# tviic2d6m register map
Vendor: Infineon Technologies; Series: TVIIC2D6M; File version: 1.0
CPU: CM7 r0p1, little endian, MPU, FPU, double-precision FPU, I-cache, D-cache, VTOR, ITCM, DTCM, 3 interrupt priority bits, 16 interrupts
Registers are 32-bit, read-write, reset 0x0 unless marked. A register's access mark holds for its fields unless they carry their own. Offsets are from the block's base; [hi:lo] are bit positions; <NAME> marks a mode.

## DAC0 — DAC
Base 0x40840000
0x00 CTL — Control
  [31] ENABLED — DAC IP enable: '0': Disabled. If DAC is disabled, all non-retained MMIO registers (e.g. the TX_FIFO_STATUS and INTR_TX registers) have their fields reset to their default value. SRAM content is not retained. Analog DAC output is disabled and powered down irrespective of DAC_EN. '1': Enabled.
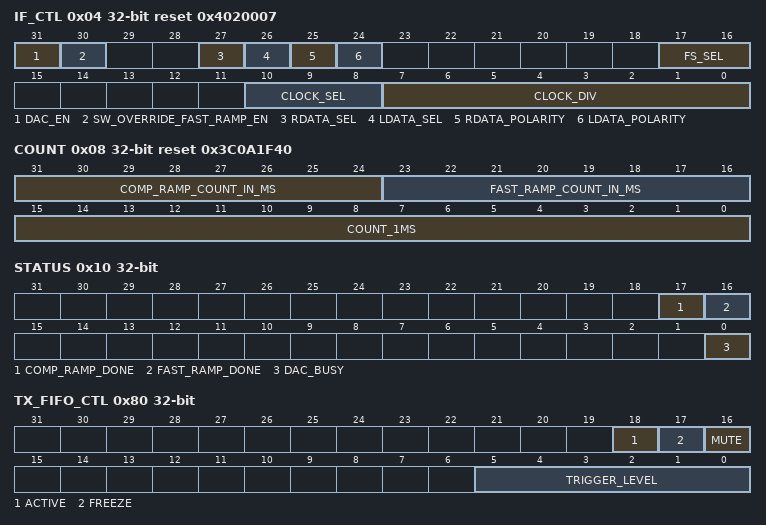
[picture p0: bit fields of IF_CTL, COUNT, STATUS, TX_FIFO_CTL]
0x04 IF_CTL reset 0x4020007 — Interface Control
  [31] DAC_EN — DAC Analog Enable. '0' - DAC Opamp and DAC COM analog bias generator is disabled. '1' - DAC Opamp and DAC COM analog bias generator is enabled. Note that after enabling the DAC Analog circuit, it requires 70ms to be stable. The same ramp up time applies when waking up from DeepSleep. DACEN is only valid when ENABLED=1. Note: This bit does not 'silent' the AudioDAC. CTL.ENABLED=0 is required to 'slient' the AudioDAC
  [30] SW_OVERRIDE_FAST_RAMP_EN — SW Override Fast Ramp enable. '0' - No SW override for fast ramp enable. HW controls the fast ramp enable. '1' - SW override for fast ramp enable. HW control is disabled. SW set the Fast Ramp enable before DAC_EN is set to 1. When SW override is used, 1. SW needs to disable the fast ramp enable by clearing this bit after the fast ramp up circuit is complete i.e. 10ms after setting DAC_EN. 2. After that, SW needs to ensure the DAC's stabilization time is met (i.e. 60ms after disabling the fast ramp circuit) before starting transactions to DAC.
  [27] RDATA_SEL — Right Data Selection. Specifies selection of the channel's 16-bit PCM data from the source FIFO data[31:0]: '0': data[15:0] (default setting). '1': data[31:16].
    0=DATA_LOW (N/A); 1=DATA_HIGH (N/A)
  [26] LDATA_SEL — Left Data Selection. Specifies selection of the channel's 16-bit PCM data from the source FIFO data[31:0]: '0': data[15:0]. '1': data[31:16] (default setting). Note: LDATA_SEL and RDATA_SEL are used to specify mono and stereo audio formats.
    0=DATA_LOW (N/A); 1=DATA_HIGH (N/A)
  [25] RDATA_POLARITY — Right Data polarity. '0' - No change in Right data. '1' - Invert (2's complement) Right data. The name of this field corresponds to the default setting. The function of this field always inverts bits 15:0 before the data is written into the FIFO. RDATA_SEL does not affect which bits are inverted.
  [24] LDATA_POLARITY — Left Data polarity. '0' - No change in Left data. '1' - Invert (2's complement) Left data. The name of this field corresponds to the default setting. The function of this field always inverts bits 31:16 before the data is written into the FIFO. LDATA_SEL does not affect which bits are inverted.
  [17:16] FS_SEL
    0=RSVD (N/A); 1=256FS_128OSR (N/A); 2=256FS_256OSR (N/A); 3=512FS_512OSR (N/A)
  [10:8] CLOCK_SEL — Interface clock clk_if selection: '0': SRSS clock clk_if_srss. '1'-'3': Clock 'clk_if' is off. '4': Master interface clock 'dac_mck'. '5'-'7': Clock 'clk_if' is off.
    0=SEL_SRSS_CLOCK (N/A); 1=SEL_CLK_IF_OFF (N/A); 4=SEL_DAC_MCK (N/A)
  [7:0] CLOCK_DIV — Interface clock divider (legal range [0, 255]). The DAC system clock clk_dac is defined as clk_if / (CLOCK_DIV + 1). CLOCK_DIV should be set to an odd value ([1,3,5,...255]) or 0 (divide by 1), to ensure a 50/50 percent duty cycle clock output. '0': clk_dac frequency is clk_if frequency (1 clk_dac cycle consists of 1 clk_if cycles). '1': clk_dac frequency is 1/2 clk_if frequency (1 clk_dac cycle consists of 2 clk_if cycles). '2': clk_dac frequency is 1/3 clk_if frequency. Note: results in a non 50/50 percent duty cycle. ... '255': clk_dac frequency is 1/256 clk_if frequency. Note: This field can only be changed when CLOCK_SEL= clk_if off.
0x08 COUNT reset 0x3C0A1F40
  [31:24] COMP_RAMP_COUNT_IN_MS — Complete Ramp count in ms. Specifies the number of counts in ms for the complete ramp circuit. The count takes place after the fast ramp count is complete. E.g. COMP_RAMP_COUNT_IN_MS=60 means that HW starts counting after disabling fast ramp circuit and stops counting after 60ms. HW sets STATUS.COMP_RAMP_DONE=1 after counting is complete.
  [23:16] FAST_RAMP_COUNT_IN_MS — Fast Ramp count in ms. Specifies the number of counts in ms for the fast ramp circuit. HW will enable the fast ramp circuit when counting is in progress. HW will disable the fast ramp circuit when counting is complete. E.g. FAST_RAMP_COUNT_IN_MS=10 means that HW enables the fast ramp circuit when it starts counting and disable the fast ramp circuit after 10ms. HW sets STATUS.FAST_RAMP_DONE=1 after counting is complete.
  [15:0] COUNT_1MS — Count for 1ms with clk_timer. Specifies the number of counts to achieve 1ms based on clk_timer (1 count represent 1 clk_timer period). This field needs to be programmed before IF_CTL.DAC_EN=1.
0x10 STATUS ro
  [17] COMP_RAMP_DONE — Complete Ramp Done. '0' - Complete Ramp is not complete. '1' - Complete Ramp is complete. The ramping of the circuit is deemed complete based on time specified in COMP_RAMP_COUNT_IN_MS. Timer starts counting if FAST_RAMP_DONE=1 and COMP_RAMP_DONE=0 and IF_CTL.DAC_EN=1 This bit transition from '0'->'1' will cause HW to set TX_INTR.RAMP_COMPLETE=1. SW clearing TX_INTR.RAMP_COMPLETE=0 will not have effect of this status bit.
  [16] FAST_RAMP_DONE — Fast Ramp Done. '0' - Fast ramping is not complete. '1' - Fast ramp circuit is complete. The fast ramp circuit is deemed complete based on time specified in FAST_RAMP_COUNT_IN_MS. Timer starts counting if FAST_RAMP_DONE=0 and IF_CTL.DAC_EN=1.
  [0] DAC_BUSY — DAC Busy. '0' - DAC is idle. '1' - Indicates that FS_SEL is in the middle of synchronizing to clk_if domain. SW must not change FS_SEL until DAC_BUSY=0.
0x80 TX_FIFO_CTL — TX FIFO control
  [18] ACTIVE — Activate functionality: '0': The FIFO_UNDERFLOW interrupt cause will not be activated. HW uses a constant PCM data value of '0' if ACTIVE=0 prior to FIFO content is available. Otherwise, PCM data is transmitted from the TX FIFO when finishing an audio packet stream. '1': The FIFO_UNDERFLOW interrupt may be activated (when an underflow event occurs). PCM data is transmitted from the TX FIFO. Note: This functionality is intended for startup for an audio packet stream when ACTIVE=0->1. PCM data is transmitted from the TX FIFO throughout ACTIVE=1. An audio packet stream ends when FIFO is empty and ACTIVE=0. HW uses a constant PCM data value of '0' if TX FIFO is empty regardless of ACTIVE=0/1.
  [17] FREEZE — Freeze functionality: '0': HW uses TX FIFO data and advances the FIFO read pointer. '1': HW uses a constant PCM data value of '0' (the FIFO data is not used). HW reads from the TX FIFO have no effect: freeze will not advance the FIFO read pointer. Note: This functionality is intended for debugging purposes.
  [16] MUTE — Mute functionality: '0': HW uses TX FIFO data. '1'- HW uses a constant PCM data value of '0'. Mute does advance the FIFO read pointer.
  [5:0] TRIGGER_LEVEL — Trigger level. When the TX FIFO has less entries than the number of this field, a transmitter trigger event is generated: - INTR_TX.FIFO_TRIGGER = (# FIFO entries < TRIGGER_LEVEL) Note: Setting TRIGGER_LEVEL=0 means trigger will not be set.
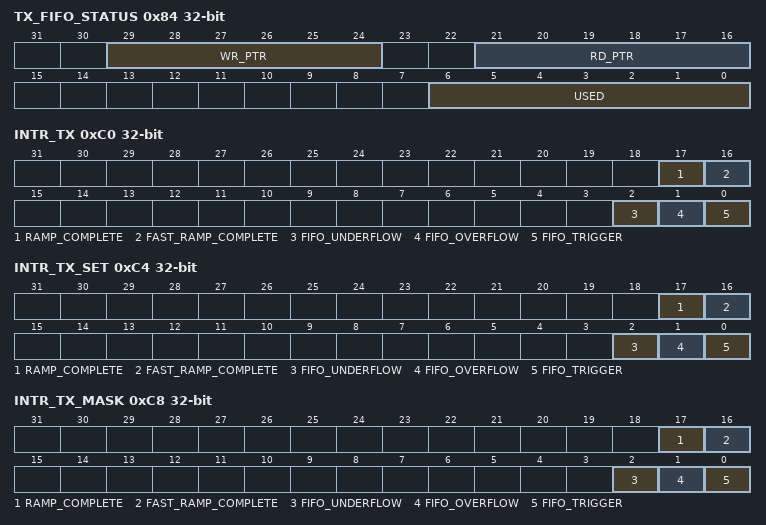
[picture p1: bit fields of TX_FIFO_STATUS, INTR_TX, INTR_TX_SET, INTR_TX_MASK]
0x84 TX_FIFO_STATUS ro
  [29:24] WR_PTR — TX FIFO write pointer: FIFO location at which a new data is written by the hardware. Note: This functionality is intended for debugging purposes.
  [21:16] RD_PTR — TX FIFO read pointer: FIFO location from which a data is read. Note: This functionality is intended for debugging purposes.
  [6:0] USED — Number of used/occupied entries in the TX FIFO. The field value is in the range [0, 64]. When '0', the FIFO is empty. When '64', the FIFO is full.
0x88 TX_FIFO_WR wo — TX FIFO write
  [31:0] DATA — Data written to the TX FIFO. Writing adds the data to the TX FIFO; i.e. behavior is similar to that of a PUSH operation (TX_FIFO_STATUS.WR_PTR is incremented and TX_FIFO_STATUS.USED is incremented). -16-bit left PCM data = DATA[31:16] -16-bit right PCM data = DATA[15:0] Note: Writing to a full TX FIFO activates INTR.TX_FIFO_OVERFLOW.
0xC0 INTR_TX — Interrupt
  [17] RAMP_COMPLETE write-1-clears — HW sets this field to '1', when ramping of the DAC circuit is complete.
  [16] FAST_RAMP_COMPLETE write-1-clears — HW sets this field to '1', when fast ramping of the DAC circuit is complete.
  [2] FIFO_UNDERFLOW write-1-clears — HW sets this field to '1', when reading from an empty TX FIFO. HW tracks underflow after TX FIFO is being written to and TX_FIFO_CTL.ACTIVE==1.
  [1] FIFO_OVERFLOW write-1-clears — HW sets this field to '1', when writing to a full TX FIFO (TX_FIFO_STATUS.USED is '64').
  [0] FIFO_TRIGGER write-1-clears — HW sets this field to '1', when a TX trigger is generated.
0xC4 INTR_TX_SET — Interrupt set
  [17] RAMP_COMPLETE write-1-sets — Write this field with '1' to set corresponding INTR_TX field (a write of '0' has no effect).
  [16] FAST_RAMP_COMPLETE write-1-sets — Write this field with '1' to set corresponding INTR_TX field (a write of '0' has no effect).
  [2] FIFO_UNDERFLOW write-1-sets — Write this field with '1' to set corresponding INTR_TX field (a write of '0' has no effect).
  [1] FIFO_OVERFLOW write-1-sets — Write this field with '1' to set corresponding INTR_TX field (a write of '0' has no effect).
  [0] FIFO_TRIGGER write-1-sets — Write this field with '1' to set corresponding INTR_TX field (a write of '0' has no effect).
0xC8 INTR_TX_MASK — Interrupt mask
  [17] RAMP_COMPLETE — Mask for corresponding field in INTR_TX register.
  [16] FAST_RAMP_COMPLETE — Mask for corresponding field in INTR_TX register.
  [2] FIFO_UNDERFLOW — Mask for corresponding field in INTR_TX register.
  [1] FIFO_OVERFLOW — Mask for corresponding field in INTR_TX register.
  [0] FIFO_TRIGGER — Mask for corresponding field in INTR_TX register.
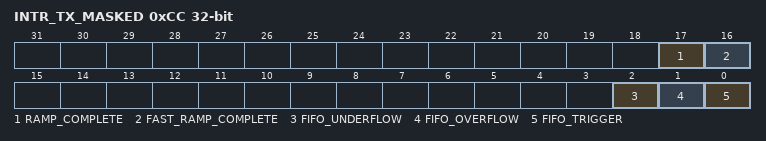
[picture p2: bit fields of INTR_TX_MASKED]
0xCC INTR_TX_MASKED ro — Interrupt masked
  [17] RAMP_COMPLETE — Logical AND of corresponding INTR_TX and INTR_TX_MASK fields.
  [16] FAST_RAMP_COMPLETE — Logical AND of corresponding INTR_TX and INTR_TX_MASK fields.
  [2] FIFO_UNDERFLOW — Logical AND of corresponding INTR_TX and INTR_TX_MASK fields.
  [1] FIFO_OVERFLOW — Logical AND of corresponding INTR_TX and INTR_TX_MASK fields.
  [0] FIFO_TRIGGER — Logical AND of corresponding INTR_TX and INTR_TX_MASK fields.
